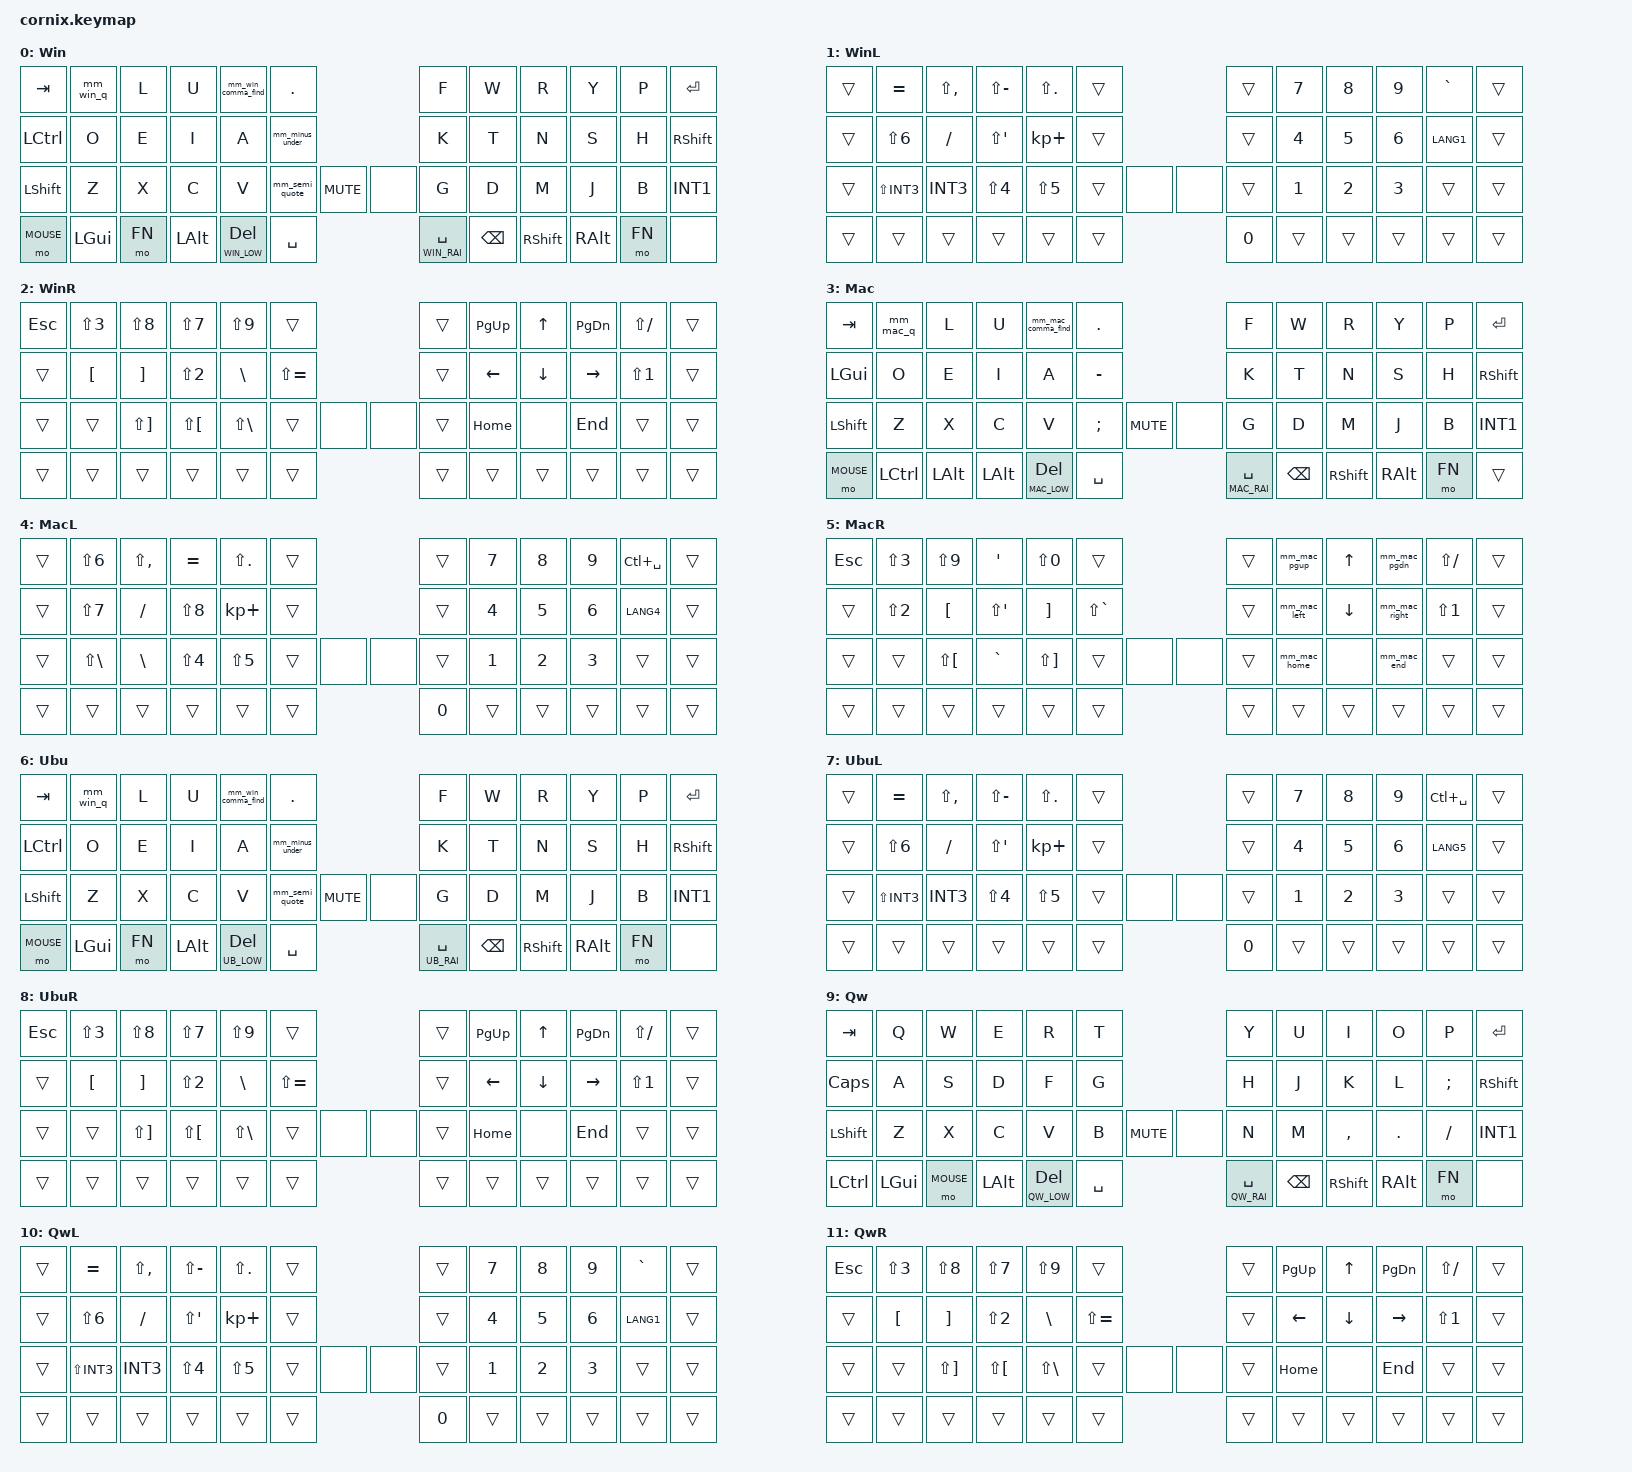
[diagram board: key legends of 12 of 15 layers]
/*
 * Cornix keymap — QMK YUKYU_LAYOUT port (15 layers)
 *
 * Layer index:
 *   0 WIN_BASE / 1 WIN_LOW / 2 WIN_RAI
 *   3 MAC_BASE / 4 MAC_LOW / 5 MAC_RAI
 *   6 UB_BASE  / 7 UB_LOW  / 8 UB_RAI
 *   9 QW_BASE  /10 QW_LOW  /11 QW_RAI
 *  12 MOUSE   /13 MOUSE2  /14 FN
 *
 * Position layout (50 slots; index 30 & 31 are encoder click positions):
 *   row0:  0  1  2  3  4  5            6  7  8  9 10 11
 *   row1: 12 13 14 15 16 17           18 19 20 21 22 23
 *   row2: 24 25 26 27 28 29  30 31    32 33 34 35 36 37
 *   row3: 38 39 40 41 42 43           44 45 46 47 48 49
 *
 * key_override_t replacements via mod-morph placed on the OS base layers.
 * Phase 1: declarative only. Option+Tab sticky is Phase 2 (custom Zephyr behavior).
 */

#include <behaviors.dtsi>
#include <dt-bindings/zmk/bt.h>
#include <dt-bindings/zmk/ext_power.h>
#include <dt-bindings/zmk/keys.h>

#define ZMK_POINTING_DEFAULT_MOVE_VAL 1800
/* スクロール速度（既定~10）。値が小さいと最初の1ノッチが貯まるまで
 * 待たされ、押下→スクロール開始の遅れとして体感される。上げると即動き出す。
 * 速すぎ/遅すぎなら 15〜30 の範囲で調整。 */
#define ZMK_POINTING_DEFAULT_SCRL_VAL 20

#include <dt-bindings/zmk/pointing.h>

/* レイヤータップ(&lt)の判定方式を上書き。
 * hold-preferred: ホールド中に別キーを押した瞬間、即レイヤーに切り替わる。
 *                 （ロール打ちで誤爆するなら "balanced" に変えると折衷的になる）
 * tapping-term-ms: この時間ホールドし続けても自動でホールド成立（単独ホールド用）。
 * quick-tap-ms: タップ直後この時間内に再度押すとタップキーを連射できる(DEL/SPACE長押し用)。
 */
&lt {
    flavor = "hold-preferred";
    tapping-term-ms = <200>;
    quick-tap-ms = <175>;
};

#define WIN_BASE 0
#define WIN_LOW  1
#define WIN_RAI  2
#define MAC_BASE 3
#define MAC_LOW  4
#define MAC_RAI  5
#define UB_BASE  6
#define UB_LOW   7
#define UB_RAI   8
#define QW_BASE  9
#define QW_LOW  10
#define QW_RAI  11
#define MOUSE   12
#define MOUSE2  13
#define FN      14

/ {
    behaviors {
        /* ===== Win/Ubuntu overrides (key_override_t with layers 0,1,2,6,7,8) ===== */

        /* Shift+- -> Shift+INT1 ( _ on JIS) */
        mm_minus_under: mm_minus_under {
            compatible = "zmk,behavior-mod-morph";
            #binding-cells = <0>;
            bindings = <&kp MINUS>, <&kp LS(INT1)>;
            mods = <(MOD_LSFT|MOD_RSFT)>;
        };

        /* Shift+; -> ' (KC_QUOT, : on JIS) */
        mm_semi_quote: mm_semi_quote {
            compatible = "zmk,behavior-mod-morph";
            #binding-cells = <0>;
            bindings = <&kp SEMI>, <&kp SQT>;
            mods = <(MOD_LSFT|MOD_RSFT)>;
        };

        /* Ctrl+, -> Ctrl+F  (find) */
        mm_win_comma_find: mm_win_comma_find {
            compatible = "zmk,behavior-mod-morph";
            #binding-cells = <0>;
            bindings = <&kp COMMA>, <&kp LC(F)>;
            mods = <(MOD_LCTL|MOD_RCTL)>;
        };

        /* Ctrl+Q -> Ctrl+Q ;  Ctrl+Shift+Q -> Alt+F4
         * outer: Ctrl detect / inner: Shift detect
         */
        /* Alt+F4 を「Ctrlも Shiftも剥がして」クリーンに送る strip-morph。
         * mod-morph のマスクは「各段が、自分のトリガmodを、自分が"直接"出す
         * キーコードに対してだけ」効く。よって外側(Ctrl)・内側(Shift)のマスクは、
         * 最終キーコードを実際に出すこのノードまで伝播しない（入れ子の罠）。
         * 対策は単純で、最終出力点であるここで Ctrl・Shift を両方マスクする。
         * このノードへは必ず Ctrl+Shift 同時押しの経路でしか到達しないので、
         * morph側(右)が必ず発動し、keep-mods=0(既定)で両modが除去される。
         */
        af4_clean: af4_clean {
            compatible = "zmk,behavior-mod-morph";
            #binding-cells = <0>;
            bindings = <&kp LA(F4)>, <&kp LA(F4)>;
            mods = <(MOD_LCTL|MOD_RCTL|MOD_LSFT|MOD_RSFT)>;
        };
        mm_win_q_inner: mm_win_q_inner {
            compatible = "zmk,behavior-mod-morph";
            #binding-cells = <0>;
            bindings = <&kp LC(Q)>, <&af4_clean>;
            mods = <(MOD_LSFT|MOD_RSFT)>;
        };
        mm_win_q: mm_win_q {
            compatible = "zmk,behavior-mod-morph";
            #binding-cells = <0>;
            bindings = <&kp Q>, <&mm_win_q_inner>;
            mods = <(MOD_LCTL|MOD_RCTL)>;
        };

        /* ===== Mac overrides (key_override_t with layers 3,4,5) ===== */

        /* Cmd+, -> Cmd+F */
        mm_mac_comma_find: mm_mac_comma_find {
            compatible = "zmk,behavior-mod-morph";
            #binding-cells = <0>;
            bindings = <&kp COMMA>, <&kp LG(F)>;
            mods = <(MOD_LGUI|MOD_RGUI)>;
        };

        /* Cmd+Q -> none (block) ;  Cmd+Shift+Q -> Cmd+Q */
        mm_mac_q_inner: mm_mac_q_inner {
            compatible = "zmk,behavior-mod-morph";
            #binding-cells = <0>;
            bindings = <&none>, <&kp LG(Q)>;
            mods = <(MOD_LSFT|MOD_RSFT)>;
        };
        mm_mac_q: mm_mac_q {
            compatible = "zmk,behavior-mod-morph";
            #binding-cells = <0>;
            bindings = <&kp Q>, <&mm_mac_q_inner>;
            mods = <(MOD_LGUI|MOD_RGUI)>;
        };

        /* Mac Raise LEFT:
         *   plain LEFT
         *   Cmd+LEFT  -> Option+LEFT (word back on Mac)
         *   Opt+LEFT  -> Cmd+[       (history back; with negmods Ctrl/Shift/Gui)
         * outer: GUI / inner: ALT
         */
        mm_mac_left_inner: mm_mac_left_inner {
            compatible = "zmk,behavior-mod-morph";
            #binding-cells = <0>;
            bindings = <&kp LEFT>, <&kp LG(LBKT)>;
            mods = <(MOD_LALT|MOD_RALT)>;
        };
        mm_mac_left: mm_mac_left {
            compatible = "zmk,behavior-mod-morph";
            #binding-cells = <0>;
            bindings = <&mm_mac_left_inner>, <&kp LA(LEFT)>;
            mods = <(MOD_LGUI|MOD_RGUI)>;
        };

        /* Mac Raise RIGHT: mirror of LEFT */
        mm_mac_right_inner: mm_mac_right_inner {
            compatible = "zmk,behavior-mod-morph";
            #binding-cells = <0>;
            bindings = <&kp RIGHT>, <&kp LG(RBKT)>;
            mods = <(MOD_LALT|MOD_RALT)>;
        };
        mm_mac_right: mm_mac_right {
            compatible = "zmk,behavior-mod-morph";
            #binding-cells = <0>;
            bindings = <&mm_mac_right_inner>, <&kp LA(RIGHT)>;
            mods = <(MOD_LGUI|MOD_RGUI)>;
        };

        /* Cmd+PgUp -> Opt+Cmd+Left (Mac tab back) */
        mm_mac_pgup: mm_mac_pgup {
            compatible = "zmk,behavior-mod-morph";
            #binding-cells = <0>;
            bindings = <&kp PG_UP>, <&kp LA(LG(LEFT))>;
            mods = <(MOD_LGUI|MOD_RGUI)>;
        };

        /* Cmd+PgDn -> Opt+Cmd+Right (Mac tab forward) */
        mm_mac_pgdn: mm_mac_pgdn {
            compatible = "zmk,behavior-mod-morph";
            #binding-cells = <0>;
            bindings = <&kp PG_DN>, <&kp LA(LG(RIGHT))>;
            mods = <(MOD_LGUI|MOD_RGUI)>;
        };

        /* Mac Raise HOME:
         *   Cmd+HOME   -> Cmd+Up
         *   Shift+HOME -> Cmd+Shift+Left
         */
        mm_mac_home_inner: mm_mac_home_inner {
            compatible = "zmk,behavior-mod-morph";
            #binding-cells = <0>;
            bindings = <&kp HOME>, <&kp LG(LS(LEFT))>;
            mods = <(MOD_LSFT|MOD_RSFT)>;
        };
        mm_mac_home: mm_mac_home {
            compatible = "zmk,behavior-mod-morph";
            #binding-cells = <0>;
            bindings = <&mm_mac_home_inner>, <&kp LG(UP)>;
            mods = <(MOD_LGUI|MOD_RGUI)>;
        };

        /* Mac Raise END: mirror of HOME */
        mm_mac_end_inner: mm_mac_end_inner {
            compatible = "zmk,behavior-mod-morph";
            #binding-cells = <0>;
            bindings = <&kp END>, <&kp LG(LS(RIGHT))>;
            mods = <(MOD_LSFT|MOD_RSFT)>;
        };
        mm_mac_end: mm_mac_end {
            compatible = "zmk,behavior-mod-morph";
            #binding-cells = <0>;
            bindings = <&mm_mac_end_inner>, <&kp LG(DOWN)>;
            mods = <(MOD_LGUI|MOD_RGUI)>;
        };
    };

    keymap {
        compatible = "zmk,keymap";

        /* ============================================================ */
        /* Layer 0: WIN_BASE                                              */
        /* row3: TAB Q L U , .      F W R Y P ENT                         */
        /* row2: CTL O E I A -      K T N S H RSFT                        */
        /* row1: SFT Z X C V ;  [n][n]  G D M J B INT1                    */
        /* row0: MO12 LGUI MO14 LALT LSFT LT1/DEL LT2/SPC BSPC RSFT RALT MO14 NO */
        /* with mod-morphs at Q / COMMA / MINUS / SEMI                    */
        /* ============================================================ */
        win_base {
            display-name = "Win";
            bindings = <
&kp TAB    &mm_win_q     &kp L        &kp U        &mm_win_comma_find  &kp DOT                          &kp F                  &kp W        &kp R        &kp Y       &kp P     &kp ENTER
&kp LCTRL  &kp O         &kp E        &kp I        &kp A               &mm_minus_under                  &kp K                  &kp T        &kp N        &kp S       &kp H     &kp RSHIFT
&kp LSHFT  &kp Z         &kp X        &kp C        &kp V               &mm_semi_quote   &kp C_MUTE   &none   &kp G             &kp D        &kp M        &kp J       &kp B     &kp INT1
&mo MOUSE  &kp LGUI      &mo FN       &kp LALT     &lt WIN_LOW DEL     &kp SPACE                        &lt WIN_RAI SPACE      &kp BSPC     &kp RSHIFT   &kp RALT    &mo FN    &none
            >;
            sensor-bindings = <&inc_dec_kp C_VOL_UP C_VOL_DN &inc_dec_kp PG_UP PG_DN>;
        };

        /* Layer 1: WIN_LOW  (numbers / shifted symbols) */
        win_low {
            display-name = "WinL";
            bindings = <
&trans     &kp EQUAL     &kp LS(COMMA) &kp LS(MINUS) &kp LS(DOT)        &trans                            &trans                &kp N7       &kp N8       &kp N9      &kp GRAVE &trans
&trans     &kp LS(N6)    &kp SLASH     &kp LS(SQT)   &kp KP_PLUS        &trans                            &trans                &kp N4       &kp N5       &kp N6      &kp LANG1 &trans
&trans     &kp LS(INT3)  &kp INT3      &kp LS(N4)    &kp LS(N5)         &trans        &none   &none    &trans                &kp N1       &kp N2       &kp N3      &trans    &trans
&trans     &trans        &trans        &trans        &trans             &trans                            &kp N0                &trans       &trans       &trans      &trans    &trans
            >;
            sensor-bindings = <&inc_dec_kp C_VOL_UP C_VOL_DN &inc_dec_kp PG_UP PG_DN>;
        };

        /* Layer 2: WIN_RAI  (symbols / arrows) */
        win_rai {
            display-name = "WinR";
            bindings = <
&kp ESC    &kp LS(N3)    &kp LS(N8)    &kp LS(N7)    &kp LS(N9)         &trans                            &trans                &kp PG_UP    &kp UP       &kp PG_DN   &kp LS(SLASH) &trans
&trans     &kp LBKT      &kp RBKT      &kp LS(N2)    &kp BSLH           &kp LS(EQUAL)                     &trans                &kp LEFT     &kp DOWN     &kp RIGHT   &kp LS(N1)    &trans
&trans     &trans        &kp LS(RBKT)  &kp LS(LBKT)  &kp LS(BSLH)       &trans           &none   &none    &trans                &kp HOME     &none        &kp END     &trans        &trans
&trans     &trans        &trans        &trans        &trans             &trans                            &trans                &trans       &trans       &trans      &trans        &trans
            >;
            sensor-bindings = <&inc_dec_kp C_VOL_UP C_VOL_DN &inc_dec_kp PG_UP PG_DN>;
        };

        /* ============================================================ */
        /* Layer 3: MAC_BASE                                              */
        /* row3: TAB Q L U , .      F W R Y P ENT                         */
        /* row2: GUI O E I A -      K T N S H RSFT      <- left col GUI   */
        /* row1: SFT Z X C V ;  [n][n]  G D M J B INT1                    */
        /* row0: MO12 LCTL LALT LALT LSFT LT4/DEL LT5/SPC BSPC RSFT RALT MO14 -_- */
        /* with mod-morphs at Q (mac) / COMMA (mac)                        */
        /* ============================================================ */
        mac_base {
            display-name = "Mac";
            bindings = <
&kp TAB    &mm_mac_q     &kp L        &kp U        &mm_mac_comma_find  &kp DOT                          &kp F                  &kp W        &kp R        &kp Y       &kp P     &kp ENTER
&kp LGUI   &kp O         &kp E        &kp I        &kp A               &kp MINUS                        &kp K                  &kp T        &kp N        &kp S       &kp H     &kp RSHIFT
&kp LSHFT  &kp Z         &kp X        &kp C        &kp V               &kp SEMI         &kp C_MUTE   &none   &kp G                  &kp D        &kp M        &kp J       &kp B     &kp INT1
&mo MOUSE  &kp LCTRL     &kp LALT     &kp LALT     &lt MAC_LOW DEL     &kp SPACE                        &lt MAC_RAI SPACE      &kp BSPC     &kp RSHIFT   &kp RALT    &mo FN    &trans
            >;
            sensor-bindings = <&inc_dec_kp C_VOL_UP C_VOL_DN &inc_dec_kp PG_UP PG_DN>;
        };

        /* Layer 4: MAC_LOW (numbers; Mac-specific shifted symbols) */
        mac_low {
            display-name = "MacL";
            bindings = <
&trans     &kp LS(N6)    &kp LS(COMMA) &kp EQUAL     &kp LS(DOT)        &trans                            &trans                &kp N7       &kp N8       &kp N9      &kp LC(SPACE) &trans
&trans     &kp LS(N7)    &kp SLASH     &kp LS(N8)    &kp KP_PLUS        &trans                            &trans                &kp N4       &kp N5       &kp N6      &kp LANG4     &trans
&trans     &kp LS(BSLH)  &kp BSLH      &kp LS(N4)    &kp LS(N5)         &trans        &none   &none    &trans                &kp N1       &kp N2       &kp N3      &trans        &trans
&trans     &trans        &trans        &trans        &trans             &trans                            &kp N0                &trans       &trans       &trans      &trans        &trans
            >;
            sensor-bindings = <&inc_dec_kp C_VOL_UP C_VOL_DN &inc_dec_kp PG_UP PG_DN>;
        };

        /* Layer 5: MAC_RAI (symbols / arrows; with Mac-specific overrides on PgUp/Dn/Left/Right/Home/End) */
        mac_rai {
            display-name = "MacR";
            bindings = <
&kp ESC    &kp LS(N3)    &kp LS(N9)    &kp SQT       &kp LS(N0)         &trans                            &trans                &mm_mac_pgup &kp UP       &mm_mac_pgdn &kp LS(SLASH) &trans
&trans     &kp LS(N2)    &kp LBKT      &kp LS(SQT)   &kp RBKT           &kp LS(GRAVE)                     &trans                &mm_mac_left &kp DOWN     &mm_mac_right &kp LS(N1)   &trans
&trans     &trans        &kp LS(LBKT)  &kp GRAVE     &kp LS(RBKT)       &trans           &none   &none    &trans                &mm_mac_home &none        &mm_mac_end  &trans        &trans
&trans     &trans        &trans        &trans        &trans             &trans                            &trans                &trans       &trans       &trans       &trans        &trans
            >;
            sensor-bindings = <&inc_dec_kp C_VOL_UP C_VOL_DN &inc_dec_kp PG_UP PG_DN>;
        };

        /* ============================================================ */
        /* Layer 6: UB_BASE (Ubuntu) -- same physical map as Win, same mod-morphs */
        /* ============================================================ */
        ub_base {
            display-name = "Ubu";
            bindings = <
&kp TAB    &mm_win_q     &kp L        &kp U        &mm_win_comma_find  &kp DOT                          &kp F                  &kp W        &kp R        &kp Y       &kp P     &kp ENTER
&kp LCTRL  &kp O         &kp E        &kp I        &kp A               &mm_minus_under                  &kp K                  &kp T        &kp N        &kp S       &kp H     &kp RSHIFT
&kp LSHFT  &kp Z         &kp X        &kp C        &kp V               &mm_semi_quote   &kp C_MUTE   &none   &kp G                  &kp D        &kp M        &kp J       &kp B     &kp INT1
&mo MOUSE  &kp LGUI      &mo FN       &kp LALT     &lt UB_LOW DEL      &kp SPACE                        &lt UB_RAI SPACE       &kp BSPC     &kp RSHIFT   &kp RALT    &mo FN    &none
            >;
            sensor-bindings = <&inc_dec_kp C_VOL_UP C_VOL_DN &inc_dec_kp PG_UP PG_DN>;
        };

        /* Layer 7: UB_LOW (same as WinLow but LANG5 instead of LANG1) */
        ub_low {
            display-name = "UbuL";
            bindings = <
&trans     &kp EQUAL     &kp LS(COMMA) &kp LS(MINUS) &kp LS(DOT)        &trans                            &trans                &kp N7       &kp N8       &kp N9      &kp LC(SPACE) &trans
&trans     &kp LS(N6)    &kp SLASH     &kp LS(SQT)   &kp KP_PLUS        &trans                            &trans                &kp N4       &kp N5       &kp N6      &kp LANG5     &trans
&trans     &kp LS(INT3)  &kp INT3      &kp LS(N4)    &kp LS(N5)         &trans        &none   &none    &trans                &kp N1       &kp N2       &kp N3      &trans        &trans
&trans     &trans        &trans        &trans        &trans             &trans                            &kp N0                &trans       &trans       &trans      &trans        &trans
            >;
            sensor-bindings = <&inc_dec_kp C_VOL_UP C_VOL_DN &inc_dec_kp PG_UP PG_DN>;
        };

        /* Layer 8: UB_RAI (same as WinRai) */
        ub_rai {
            display-name = "UbuR";
            bindings = <
&kp ESC    &kp LS(N3)    &kp LS(N8)    &kp LS(N7)    &kp LS(N9)         &trans                            &trans                &kp PG_UP    &kp UP       &kp PG_DN   &kp LS(SLASH) &trans
&trans     &kp LBKT      &kp RBKT      &kp LS(N2)    &kp BSLH           &kp LS(EQUAL)                     &trans                &kp LEFT     &kp DOWN     &kp RIGHT   &kp LS(N1)    &trans
&trans     &trans        &kp LS(RBKT)  &kp LS(LBKT)  &kp LS(BSLH)       &trans           &none   &none    &trans                &kp HOME     &none        &kp END     &trans        &trans
&trans     &trans        &trans        &trans        &trans             &trans                            &trans                &trans       &trans       &trans      &trans        &trans
            >;
            sensor-bindings = <&inc_dec_kp C_VOL_UP C_VOL_DN &inc_dec_kp PG_UP PG_DN>;
        };

        /* ============================================================ */
        /* Layer 9: QW_BASE (plain QWERTY -- NO mod-morphs applied)      */
        /* ============================================================ */
        qw_base {
            display-name = "Qw";
            bindings = <
&kp TAB    &kp Q         &kp W        &kp E        &kp R               &kp T                            &kp Y                  &kp U        &kp I        &kp O       &kp P     &kp ENTER
&kp CAPS   &kp A         &kp S        &kp D        &kp F               &kp G                            &kp H                  &kp J        &kp K        &kp L       &kp SEMI  &kp RSHIFT
&kp LSHFT  &kp Z         &kp X        &kp C        &kp V               &kp B            &kp C_MUTE   &none   &kp N                  &kp M        &kp COMMA    &kp DOT     &kp SLASH &kp INT1
&kp LCTRL  &kp LGUI      &mo MOUSE    &kp LALT     &lt QW_LOW DEL      &kp SPACE                        &lt QW_RAI SPACE       &kp BSPC     &kp RSHIFT   &kp RALT    &mo FN    &none
            >;
            sensor-bindings = <&inc_dec_kp C_VOL_UP C_VOL_DN &inc_dec_kp PG_UP PG_DN>;
        };

        /* Layer 10: QW_LOW (same structure as Win Lower, no override applied to base) */
        qw_low {
            display-name = "QwL";
            bindings = <
&trans     &kp EQUAL     &kp LS(COMMA) &kp LS(MINUS) &kp LS(DOT)        &trans                            &trans                &kp N7       &kp N8       &kp N9      &kp GRAVE &trans
&trans     &kp LS(N6)    &kp SLASH     &kp LS(SQT)   &kp KP_PLUS        &trans                            &trans                &kp N4       &kp N5       &kp N6      &kp LANG1 &trans
&trans     &kp LS(INT3)  &kp INT3      &kp LS(N4)    &kp LS(N5)         &trans           &none   &none    &trans                &kp N1       &kp N2       &kp N3      &trans    &trans
&trans     &trans        &trans        &trans        &trans             &trans                            &kp N0                &trans       &trans       &trans      &trans    &trans
            >;
            sensor-bindings = <&inc_dec_kp C_VOL_UP C_VOL_DN &inc_dec_kp PG_UP PG_DN>;
        };

        /* Layer 11: QW_RAI */
        qw_rai {
            display-name = "QwR";
            bindings = <
&kp ESC    &kp LS(N3)    &kp LS(N8)    &kp LS(N7)    &kp LS(N9)         &trans                            &trans                &kp PG_UP    &kp UP       &kp PG_DN   &kp LS(SLASH) &trans
&trans     &kp LBKT      &kp RBKT      &kp LS(N2)    &kp BSLH           &kp LS(EQUAL)                     &trans                &kp LEFT     &kp DOWN     &kp RIGHT   &kp LS(N1)    &trans
&trans     &trans        &kp LS(RBKT)  &kp LS(LBKT)  &kp LS(BSLH)       &trans        &none   &none       &trans                &kp HOME     &none        &kp END     &trans        &trans
&trans     &trans        &trans        &trans        &trans             &trans                            &trans                &trans       &trans       &trans      &trans        &trans
            >;
            sensor-bindings = <&inc_dec_kp C_VOL_UP C_VOL_DN &inc_dec_kp PG_UP PG_DN>;
        };

        /* ============================================================ */
        /* Layer 12: MOUSE (cursor + left/right click)                    */
        /* ============================================================ */
        mouse {
            display-name = "Mse";
            bindings = <
&none      &none         &none        &none        &none               &none                            &none                  &none        &mmv MOVE_UP &none       &none     &none
&trans     &none         &none        &none        &none               &none                            &none                  &mmv MOVE_LEFT &mmv MOVE_DOWN &mmv MOVE_RIGHT &none &none
&trans     &none         &none        &none        &none               &none            &none   &none   &none                  &none        &none        &none       &none     &none
&none      &none         &none        &none        &none               &mo MOUSE2                       &mkp MB1               &mkp MB2     &none        &none       &none
            >;
        };

        /* Layer 13: MOUSE2 (wheel) */
        mouse2 {
            display-name = "Mse2";
            bindings = <
&none      &none         &none        &none        &none               &none                            &none                  &none        &msc SCRL_UP   &none     &none     &none
&trans     &none         &none        &none        &none               &none                            &none                  &msc SCRL_LEFT &msc SCRL_DOWN &msc SCRL_RIGHT &none &none
&trans     &none         &none        &none        &none               &none            &none   &none   &none                  &none        &none          &none     &none     &none
&none      &none         &none        &none        &none               &none                            &mkp MB1               &mkp MB2     &none          &none     &none     &none
            >;
        };

        /* ============================================================ */
        /* Layer 14: FN (F1-F12 + OS mode switches via TO())              */
        /* QK_BOOT omitted (user uses physical reset).                    */
        /* row3 bottom maps mode switches: TO(QW), TO(WIN), TO(MAC), TO(UBU) */
        /* ============================================================ */
        fn {
            display-name = "Fn";
            bindings = <
&trans     &kp F1        &kp F2       &kp F3       &kp F4              &trans                            &trans                &trans       &trans       &trans      &trans    &none
&trans     &kp F5        &kp F6       &kp F7       &kp F8              &trans                            &trans                &trans       &trans       &trans      &trans    &trans
&trans     &kp F9        &kp F10      &kp F11      &kp F12             &trans           &none   &none    &kp KP_NUMLOCK        &trans       &trans       &trans      &trans    &trans
&trans     &trans        &to QW_BASE  &to WIN_BASE &to MAC_BASE        &to UB_BASE                       &bt BT_SEL 0          &bt BT_SEL 1 &bt BT_SEL 2 &trans      &trans    &trans
            >;
            sensor-bindings = <&inc_dec_kp C_VOL_UP C_VOL_DN &inc_dec_kp PG_UP PG_DN>;
        };
    };
};
